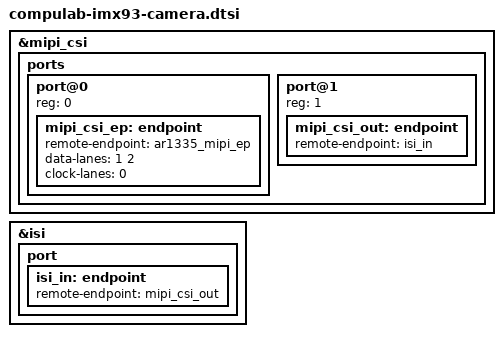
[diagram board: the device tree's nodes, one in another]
// SPDX-License-Identifier: (GPL-2.0+ OR MIT)
/* Shared two-lane sensor -> CSI receiver -> ISI graph for Linux 6.18. */
&mipi_csi {
	ports {
		#address-cells = <1>;
		#size-cells = <0>;

		port@0 {
			reg = <0>;
			mipi_csi_ep: endpoint {
				remote-endpoint = <&ar1335_mipi_ep>;
				data-lanes = <1 2>;
				clock-lanes = <0>;
			};
		};

		port@1 {
			reg = <1>;
			mipi_csi_out: endpoint {
				remote-endpoint = <&isi_in>;
			};
		};
	};
};

&isi {
	port {
		isi_in: endpoint {
			remote-endpoint = <&mipi_csi_out>;
		};
	};
};
